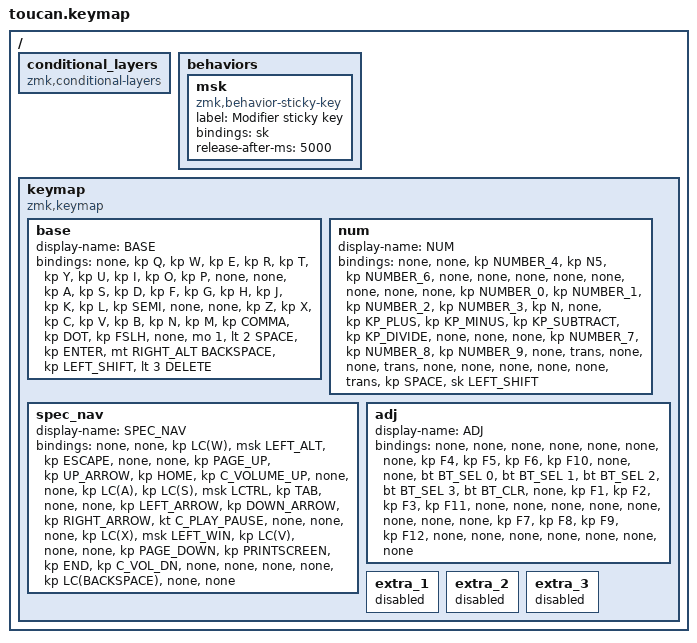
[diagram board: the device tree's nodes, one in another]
#include <behaviors.dtsi>
#include <dt-bindings/zmk/bt.h>
#include <dt-bindings/zmk/keys.h>

#define BASE 0
#define NAV  1
#define SYM  2
#define ADJ  3

/ {
    conditional_layers { compatible = "zmk,conditional-layers"; };

    behaviors {
        msk: msk {
            compatible = "zmk,behavior-sticky-key";
            label = "Modifier sticky key";
            bindings = <&sk>;
            #binding-cells = <1>;
            release-after-ms = <5000>;
        };
    };

    keymap {
        compatible = "zmk,keymap";

        base {
            display-name = "BASE";
            bindings = <
&none  &kp Q  &kp W  &kp E  &kp R  &kp T  &kp Y  &kp U  &kp I  &kp O  &kp P  &none  &none  &kp A  &kp S  &kp D  &kp F  &kp G  &kp H  &kp J  &kp K  &kp L  &kp SEMI  &none  &none  &kp Z  &kp X  &kp C  &kp V  &kp B  &kp N  &kp M  &kp COMMA  &kp DOT  &kp FSLH  &none  &mo 1  &lt 2 SPACE  &kp ENTER  &mt RIGHT_ALT BACKSPACE  &kp LEFT_SHIFT  &lt 3 DELETE
            >;
        };

        num {
            display-name = "NUM";
            bindings = <
&none  &none  &kp NUMBER_4  &kp N5  &kp NUMBER_6  &none  &none  &none  &none  &none  &none  &none  &none  &kp NUMBER_0  &kp NUMBER_1  &kp NUMBER_2  &kp NUMBER_3  &kp N  &none  &kp KP_PLUS  &kp KP_MINUS  &kp KP_SUBTRACT  &kp KP_DIVIDE  &none  &none  &none  &kp NUMBER_7  &kp NUMBER_8  &kp NUMBER_9  &none  &trans  &none  &none  &trans  &none  &none  &none  &none  &none  &trans  &kp SPACE  &sk LEFT_SHIFT
            >;
        };

        spec_nav {
            display-name = "SPEC_NAV";
            bindings = <
&none  &none  &kp LC(W)  &msk LEFT_ALT  &kp ESCAPE  &none  &none  &kp PAGE_UP  &kp UP_ARROW  &kp HOME  &kp C_VOLUME_UP  &none  &none  &kp LC(A)  &kp LC(S)  &msk LCTRL  &kp TAB  &none  &none  &kp LEFT_ARROW  &kp DOWN_ARROW  &kp RIGHT_ARROW  &kt C_PLAY_PAUSE  &none  &none  &none  &kp LC(X)  &msk LEFT_WIN  &kp LC(V)  &none  &none  &kp PAGE_DOWN  &kp PRINTSCREEN  &kp END  &kp C_VOL_DN  &none  &none  &none  &none  &kp LC(BACKSPACE)  &none  &none
            >;
        };

        adj {
            display-name = "ADJ";
            bindings = <
&none  &none  &none  &none  &none  &none  &none  &kp F4  &kp F5  &kp F6  &kp F10  &none  &none  &bt BT_SEL 0  &bt BT_SEL 1  &bt BT_SEL 2  &bt BT_SEL 3  &bt BT_CLR  &none  &kp F1  &kp F2  &kp F3  &kp F11  &none  &none  &none  &none  &none  &none  &none  &none  &kp F7  &kp F8  &kp F9  &kp F12  &none  &none  &none  &none  &none  &none  &none
            >;
        };

        extra_1 { status = "reserved"; };

        extra_2 { status = "reserved"; };

        extra_3 { status = "reserved"; };
    };
};
